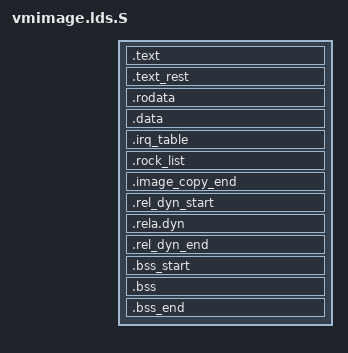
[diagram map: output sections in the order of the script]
/* SPDX-License-Identifier: GPL-2.0+ */
/*
 * (C) Copyright 2013
 * David Feng <fenghua@phytium.com.cn>
 *
 * (C) Copyright 2002
 * Gary Jennejohn, DENX Software Engineering, <garyj@denx.de>
 */

OUTPUT_FORMAT("elf64-littleaarch64", "elf64-littleaarch64", "elf64-littleaarch64")
OUTPUT_ARCH(aarch64)
ENTRY(_start)
SECTIONS
{

	. = CONFIG_SYS_TEXT_BASE;

	. = ALIGN(8);
	.text :
	{
		*(.__image_copy_start)
		HEADDIR/start.o (.text*)
	}

	.text_rest :
	{
		*(.text*)
	}

	. = ALIGN(8);
	.rodata : { *(SORT_BY_ALIGNMENT(SORT_BY_NAME(.rodata*))) }

	. = ALIGN(8);
	.data : {
		*(.data*)
	}
	. = ALIGN(8);

	. = .;

	. = ALIGN(8);
	.irq_table : {
		__section_irq_table_start = .;
		KEEP(*(SORT(.section_irq_table*)));
		__section_irq_table_end = .;
	}

	. = ALIGN(8);
	.rock_list : {
		KEEP(*(SORT(.rock_list*)));
	}

	. = ALIGN(8);

	.image_copy_end :
	{
		*(.__image_copy_end)
	}

	. = ALIGN(8);

	.rel_dyn_start :
	{
		*(.__rel_dyn_start)
	}

	.rela.dyn : {
		*(.rela*)
	}

	.rel_dyn_end :
	{
		*(.__rel_dyn_end)
	}

	_end = .;

	. = ALIGN(8);

	.bss_start : {
		KEEP(*(.__bss_start));
	}

	.bss : {
		*(.bss*)
		 . = ALIGN(8);
	}

	.bss_end : {
		KEEP(*(.__bss_end));
	}

	/DISCARD/ : { *(.dynsym) }
	/DISCARD/ : { *(.dynstr*) }
	/DISCARD/ : { *(.dynamic*) }
	/DISCARD/ : { *(.plt*) }
	/DISCARD/ : { *(.interp*) }
	/DISCARD/ : { *(.gnu*) }
}
